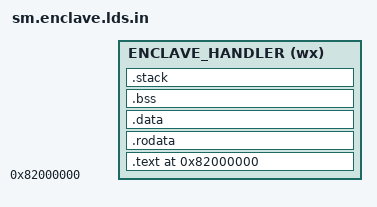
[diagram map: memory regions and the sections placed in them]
#include <parameters.h>

OUTPUT_ARCH( "riscv" )
ENTRY( enclave_handler_entry )

MEMORY
{
  ENCLAVE_HANDLER (wx) :  ORIGIN = 0x82000000,  LENGTH = HANDLER_LEN
}

SECTIONS
{
  . = ORIGIN(ENCLAVE_HANDLER);
  .text : {
    PROVIDE( enclave_handler_entry = . );
    KEEP( *(.text.entry) )
    *(.text.*)
    *(.text)
  } > ENCLAVE_HANDLER =0x0

  .rodata ALIGN(64) : {
    *(.rodata)  /* read-only data */
    *(.rodata.*)
  } > ENCLAVE_HANDLER =0x0

  .data ALIGN(64)  : {
    *(.data)  /* initialized data */
    *(.data.*)
  } > ENCLAVE_HANDLER =0x0

  .bss ALIGN(64)  : {
    *(.bss)   /* uninitialized data */
    *(.bss.*)
  } > ENCLAVE_HANDLER =0x0

  .stack ALIGN(64) : {
    *(.data.stacks)
  } > ENCLAVE_HANDLER =0x0
}
